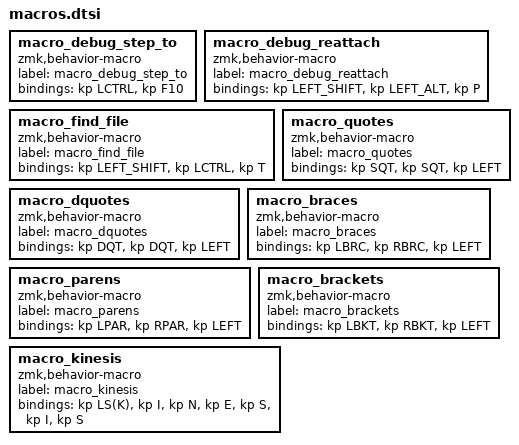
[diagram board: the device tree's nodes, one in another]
macro_debug_step_to: macro_debug_step_to{
compatible = "zmk,behavior-macro";
label = "macro_debug_step_to";
#binding-cells = <0>;
bindings = <&kp LCTRL>, <&kp F10>;
};
macro_debug_reattach: macro_debug_reattach{
compatible = "zmk,behavior-macro";
label = "macro_debug_reattach";
#binding-cells = <0>;
bindings = <&kp LEFT_SHIFT>, <&kp LEFT_ALT>, <&kp P>;
};
macro_find_file: macro_find_file{
compatible = "zmk,behavior-macro";
label = "macro_find_file";
#binding-cells = <0>;
bindings = <&kp LEFT_SHIFT>, <&kp LCTRL>, <&kp T>;
};
macro_quotes: macro_quotes{
compatible = "zmk,behavior-macro";
label = "macro_quotes";
#binding-cells = <0>;
bindings = <&kp SQT>, <&kp SQT>, <&kp LEFT>;
};
macro_dquotes: macro_dquotes{
compatible = "zmk,behavior-macro";
label = "macro_dquotes";
#binding-cells = <0>;
bindings = <&kp DQT>, <&kp DQT>, <&kp LEFT>;
};
macro_braces: macro_braces{
compatible = "zmk,behavior-macro";
label = "macro_braces";
#binding-cells = <0>;
bindings = <&kp LBRC>, <&kp RBRC>, <&kp LEFT>;
};
macro_parens: macro_parens{
compatible = "zmk,behavior-macro";
label = "macro_parens";
#binding-cells = <0>;
bindings = <&kp LPAR>, <&kp RPAR>, <&kp LEFT>;
};
macro_brackets: macro_brackets{
compatible = "zmk,behavior-macro";
label = "macro_brackets";
#binding-cells = <0>;
bindings = <&kp LBKT>, <&kp RBKT>, <&kp LEFT>;
};
macro_kinesis: macro_kinesis{
compatible = "zmk,behavior-macro";
label = "macro_kinesis";
#binding-cells = <0>;
bindings = <&kp LS(K)>, <&kp I>, <&kp N>, <&kp E>, <&kp S>, <&kp I>, <&kp S>;
};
